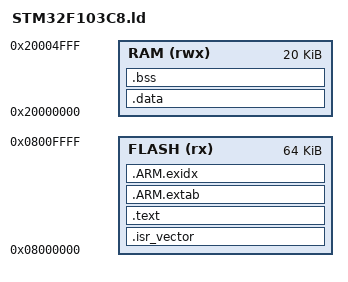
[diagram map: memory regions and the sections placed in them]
ENTRY(Reset_Handler)

MEMORY
{
    FLASH (rx)  : ORIGIN = 0x08000000, LENGTH = 64K
    RAM   (rwx) : ORIGIN = 0x20000000, LENGTH = 20K
}

_estack = ORIGIN(RAM) + LENGTH(RAM);

SECTIONS
{
    .isr_vector :
    {
        . = ALIGN(4);
        KEEP(*(.isr_vector))
        . = ALIGN(4);
    } > FLASH

    .text :
    {
        . = ALIGN(4);
        *(.text*)
        *(.rodata*)
        . = ALIGN(4);
    } > FLASH

    .ARM.extab :
    {
        *(.ARM.extab* .gnu.linkonce.armextab.*)
    } > FLASH

    .ARM.exidx :
    {
        __exidx_start = .;
        *(.ARM.exidx* .gnu.linkonce.armexidx.*)
        __exidx_end = .;
    } > FLASH

    _etext = LOADADDR(.ARM.exidx) + SIZEOF(.ARM.exidx);

    .data : AT(_etext)
    {
        . = ALIGN(4);
        _sidata = LOADADDR(.data);
        _sdata = .;
        *(.data*)
        . = ALIGN(4);
        _edata = .;
    } > RAM

    .bss :
    {
        . = ALIGN(4);
        _sbss = .;
        *(.bss*)
        *(COMMON)
        . = ALIGN(4);
        _ebss = .;
    } > RAM

    /DISCARD/ :
    {
        *(.eh_frame*)
        *(.comment)
    }
}
